# nrf9120_mlm1 register map
Vendor: Nordic Semiconductor; Series: nrf91; File version: 1
CPU: CM4 r0p1, little endian, MPU, FPU, 3 interrupt priority bits
Registers are 32-bit, read-write, reset 0x0 unless marked. A register's access mark holds for its fields unless they carry their own. Offsets are from the block's base; [hi:lo] are bit positions; 'fields as' and 'values as' point back to an identical list.

## CLOCK — Clock Management
Base 0x40005000
0x00 TASKS_HFCLKSTART wo — Start HFCLK crystal oscillator
  [0] TASKS_HFCLKSTART
    1=Trigger task
0x04 TASKS_HFCLKSTOP wo — Stop HFCLK crystal oscillator
  [0] TASKS_HFCLKSTOP
    1=Trigger task
0x08 TASKS_LFCLKSTART wo — Start LFCLK source
  [0] TASKS_LFCLKSTART
    1=Trigger task
0x0C TASKS_LFCLKSTOP wo — Stop LFCLK source
  [0] TASKS_LFCLKSTOP
    1=Trigger task
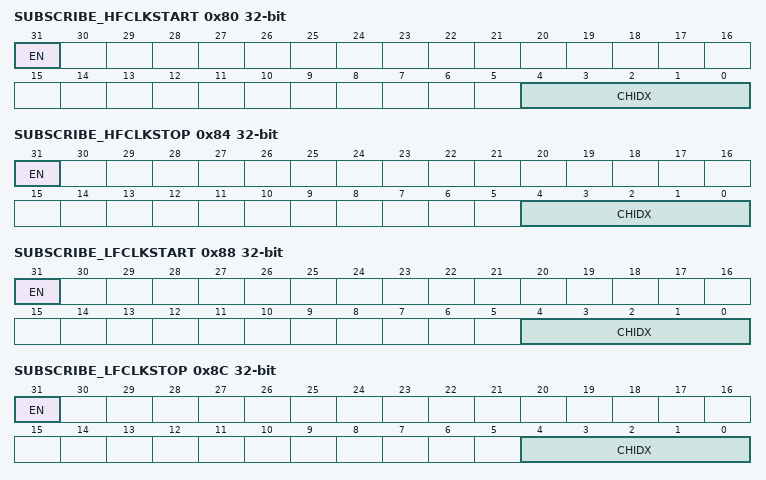
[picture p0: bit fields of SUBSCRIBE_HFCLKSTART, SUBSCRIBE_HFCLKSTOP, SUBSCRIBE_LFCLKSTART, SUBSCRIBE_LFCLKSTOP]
0x80 SUBSCRIBE_HFCLKSTART — Subscribe configuration for task HFCLKSTART
  [31] EN
    0=Disabled (Disable subscription); 1=Enabled (Enable subscription)
  [4:0] CHIDX — Channel that task HFCLKSTART will subscribe to
0x84 SUBSCRIBE_HFCLKSTOP — Subscribe configuration for task HFCLKSTOP
  [31] EN
    values as SUBSCRIBE_HFCLKSTART.EN
  [4:0] CHIDX — Channel that task HFCLKSTOP will subscribe to
0x88 SUBSCRIBE_LFCLKSTART — Subscribe configuration for task LFCLKSTART
  [31] EN
    values as SUBSCRIBE_HFCLKSTART.EN
  [4:0] CHIDX — Channel that task LFCLKSTART will subscribe to
0x8C SUBSCRIBE_LFCLKSTOP — Subscribe configuration for task LFCLKSTOP
  [31] EN
    values as SUBSCRIBE_HFCLKSTART.EN
  [4:0] CHIDX — Channel that task LFCLKSTOP will subscribe to
0x100 EVENTS_HFCLKSTARTED — HFCLK oscillator started
  [0] EVENTS_HFCLKSTARTED
    0=NotGenerated (Event not generated); 1=Generated (Event generated)
0x104 EVENTS_LFCLKSTARTED — LFCLK started
  [0] EVENTS_LFCLKSTARTED
    values as EVENTS_HFCLKSTARTED.EVENTS_HFCLKSTARTED
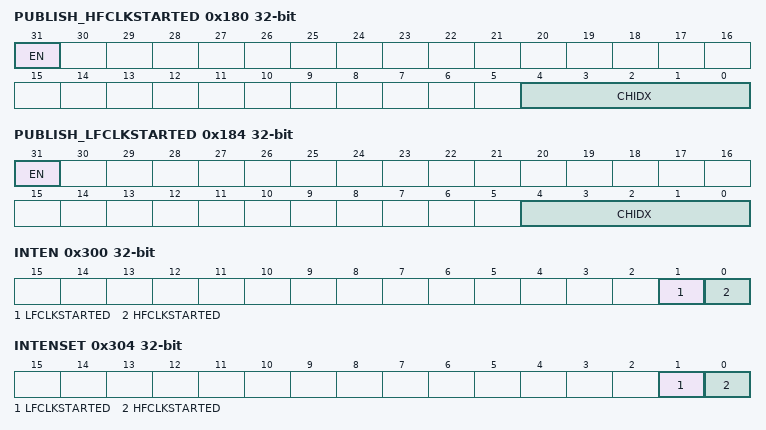
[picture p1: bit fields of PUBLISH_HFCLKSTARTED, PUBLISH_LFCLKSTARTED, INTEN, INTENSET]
0x180 PUBLISH_HFCLKSTARTED — Publish configuration for event HFCLKSTARTED
  [31] EN
    0=Disabled (Disable publishing); 1=Enabled (Enable publishing)
  [4:0] CHIDX — Channel that event HFCLKSTARTED will publish to.
0x184 PUBLISH_LFCLKSTARTED — Publish configuration for event LFCLKSTARTED
  [31] EN
    values as PUBLISH_HFCLKSTARTED.EN
  [4:0] CHIDX — Channel that event LFCLKSTARTED will publish to.
0x300 INTEN — Enable or disable interrupt
  [1] LFCLKSTARTED — Enable or disable interrupt for event LFCLKSTARTED
    0=Disabled; 1=Enabled
  [0] HFCLKSTARTED — Enable or disable interrupt for event HFCLKSTARTED
    0=Disabled; 1=Enabled
0x304 INTENSET — Enable interrupt
  [1] LFCLKSTARTED — Write '1' to enable interrupt for event LFCLKSTARTED
    on read: 0=Disabled (Read: Disabled); 1=Enabled (Read: Enabled) | on write: 1=Set (Enable)
  [0] HFCLKSTARTED — Write '1' to enable interrupt for event HFCLKSTARTED
    values as LFCLKSTARTED
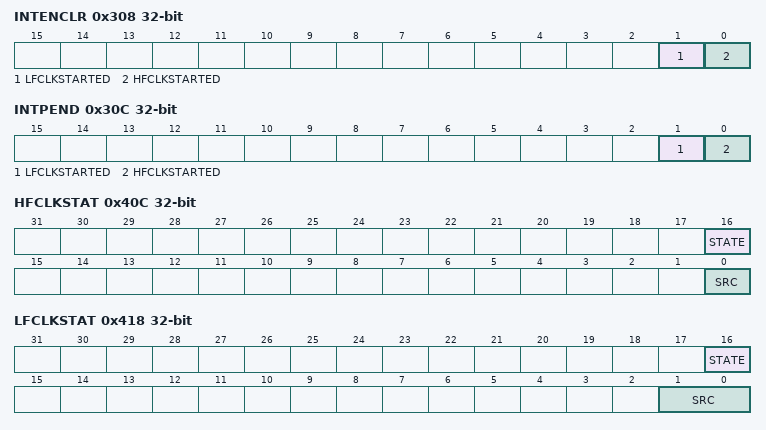
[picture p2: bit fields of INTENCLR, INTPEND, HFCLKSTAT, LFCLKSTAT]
0x308 INTENCLR — Disable interrupt
  [1] LFCLKSTARTED — Write '1' to disable interrupt for event LFCLKSTARTED
    on read: 0=Disabled (Read: Disabled); 1=Enabled (Read: Enabled) | on write: 1=Clear (Disable)
  [0] HFCLKSTARTED — Write '1' to disable interrupt for event HFCLKSTARTED
    values as LFCLKSTARTED
0x30C INTPEND ro — Pending interrupts
  [1] LFCLKSTARTED — Read pending status of interrupt for event LFCLKSTARTED
    on read: 0=NotPending (Read: Not pending); 1=Pending (Read: Pending)
  [0] HFCLKSTARTED — Read pending status of interrupt for event HFCLKSTARTED
    values as LFCLKSTARTED
0x408 HFCLKRUN ro — Status indicating that HFCLKSTART task has been triggered
  [0] STATUS — HFCLKSTART task triggered or not
    0=NotTriggered (Task not triggered); 1=Triggered (Task triggered)
0x40C HFCLKSTAT ro — Which HFCLK source is running
  [16] STATE — HFCLK state
    0=NotRunning (HFCLK not running); 1=Running (HFCLK running)
  [0] SRC — Active clock source
    0=HFINT (HFCLK clock source: HFINT - 64 MHz on-chip oscillator); 1=HFXO (HFCLK clock source: HFXO - 64 MHz clock derived from external 32 MHz crystal oscillator)
0x414 LFCLKRUN ro — Status indicating that LFCLKSTART task has been triggered
  [0] STATUS — LFCLKSTART task triggered or not
    values as HFCLKRUN.STATUS
0x418 LFCLKSTAT ro — Which LFCLK source is running
  [16] STATE — LFCLK state
    0=NotRunning (LFCLK not running); 1=Running (LFCLK running)
  [1:0] SRC — Active clock source
    0=LFULP (32.768 kHz ultra low power RC oscillator); 1=LFRC (32.768 kHz RC oscillator); 2=LFXO (32.768 kHz crystal oscillator); 3=LFSYNT (32.768 kHz synthesized from HFCLK)
0x41C LFCLKSRCCOPY ro — Copy of LFCLKSRC register, set when LFCLKSTART task was triggered LFULP is not treat as a separate clock source on Alta MLM1, where default clock source (0) is LFRC.
  [1:0] SRC — Clock source
    0=LFULP (32.768 kHz ultra low power RC oscillator (default)); 1=LFRC (32.768 kHz RC oscillator); 2=LFXO (32.768 kHz crystal oscillator); 3=LFSYNT (32.768 kHz synthesized from HFCLK)
0x430 HFCLKCURRFREQ — Current frequency of HFCLK
  [7:0] HFCLKCURRFREQ — Current High frequency clock (HCLK) frequency
    0=64M (64 MHz (default frequency)); 1=32M (32 MHz); 2=16M (16 MHz)
0x514 HFCLKSRC reset 0x100001 — Clock source for the HFCLK oscillator, and configuration of XTAL oscillator. This register shall only be written while no oscillation is present on XC1. Failing to do so may cause unexpected behaviour.
  [0] SRC — Select which HFCLK source is started by the START task
    0=HFINT (HFCLKSTART task starts HFINT oscillator); 1=HFXO (HFCLKSTART task starts HFXO oscillator)
0x518 LFCLKSRC — Clock source for the LFCLK. LFCLKSTART task starts starts a clock source selected with this register. LFULP is not treat as a separate clock source on Alta MLM1, where default clock source (0) is LFRC.
  fields as LFCLKSRCCOPY
0x558 HFCLKCTRL — HFCLK frequency configuration. The feature is not implemented on Alta MLM1. Specification of this feature is under discussion. See SAMPO-2263.
  [7:0] HCLK — High frequency clock HCLK
    64=64M (64 MHz); 32=32M (32 MHz); 16=16M (16 MHz)
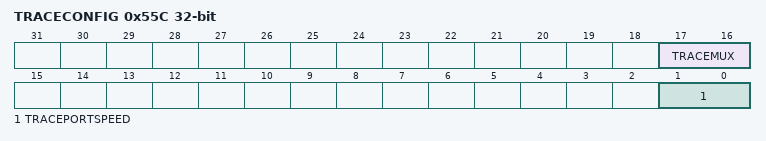
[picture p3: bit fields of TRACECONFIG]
0x55C TRACECONFIG — Clocking options for the Trace Port debug interface
  [17:16] TRACEMUX — Pin multiplexing of trace signals.
    0=GPIO (GPIOs multiplexed onto all trace-pins); 1=Serial (SWO multiplexed onto P0.18, GPIO multiplexed onto other trace pins); 2=Parallel (TRACECLK and TRACEDATA multiplexed onto P0.20, P0.18, P0.16, P0.15 and P0.14.)
  [1:0] TRACEPORTSPEED — Speed of Trace Port clock. Note that the TRACECLK pin will output this clock divided by two.
    0=32 MHz Trace Port clock (TRACECLK = 16 MHz); 1=16 MHz Trace Port clock (TRACECLK = 8 MHz); 2=8 MHz Trace Port clock (TRACECLK = 4 MHz); 3=4 MHz Trace Port clock (TRACECLK = 2 MHz)
